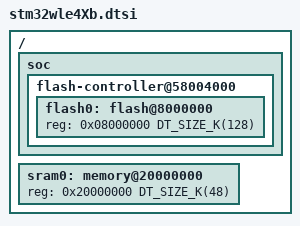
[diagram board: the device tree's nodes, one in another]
/*
 * Copyright (c) 2021 Thomas Stranger
 *
 * SPDX-License-Identifier: Apache-2.0
 */
#include <st/wl/stm32wle5.dtsi>

/ {
	soc {
		flash-controller@58004000 {
			flash0: flash@8000000 {
				reg = <0x08000000 DT_SIZE_K(128)>;
				ranges = <0 0x8000000 DT_SIZE_K(128)>;
			};
		};
	};

	sram0: memory@20000000 {
		reg = <0x20000000 DT_SIZE_K(48)>;
	};
};
